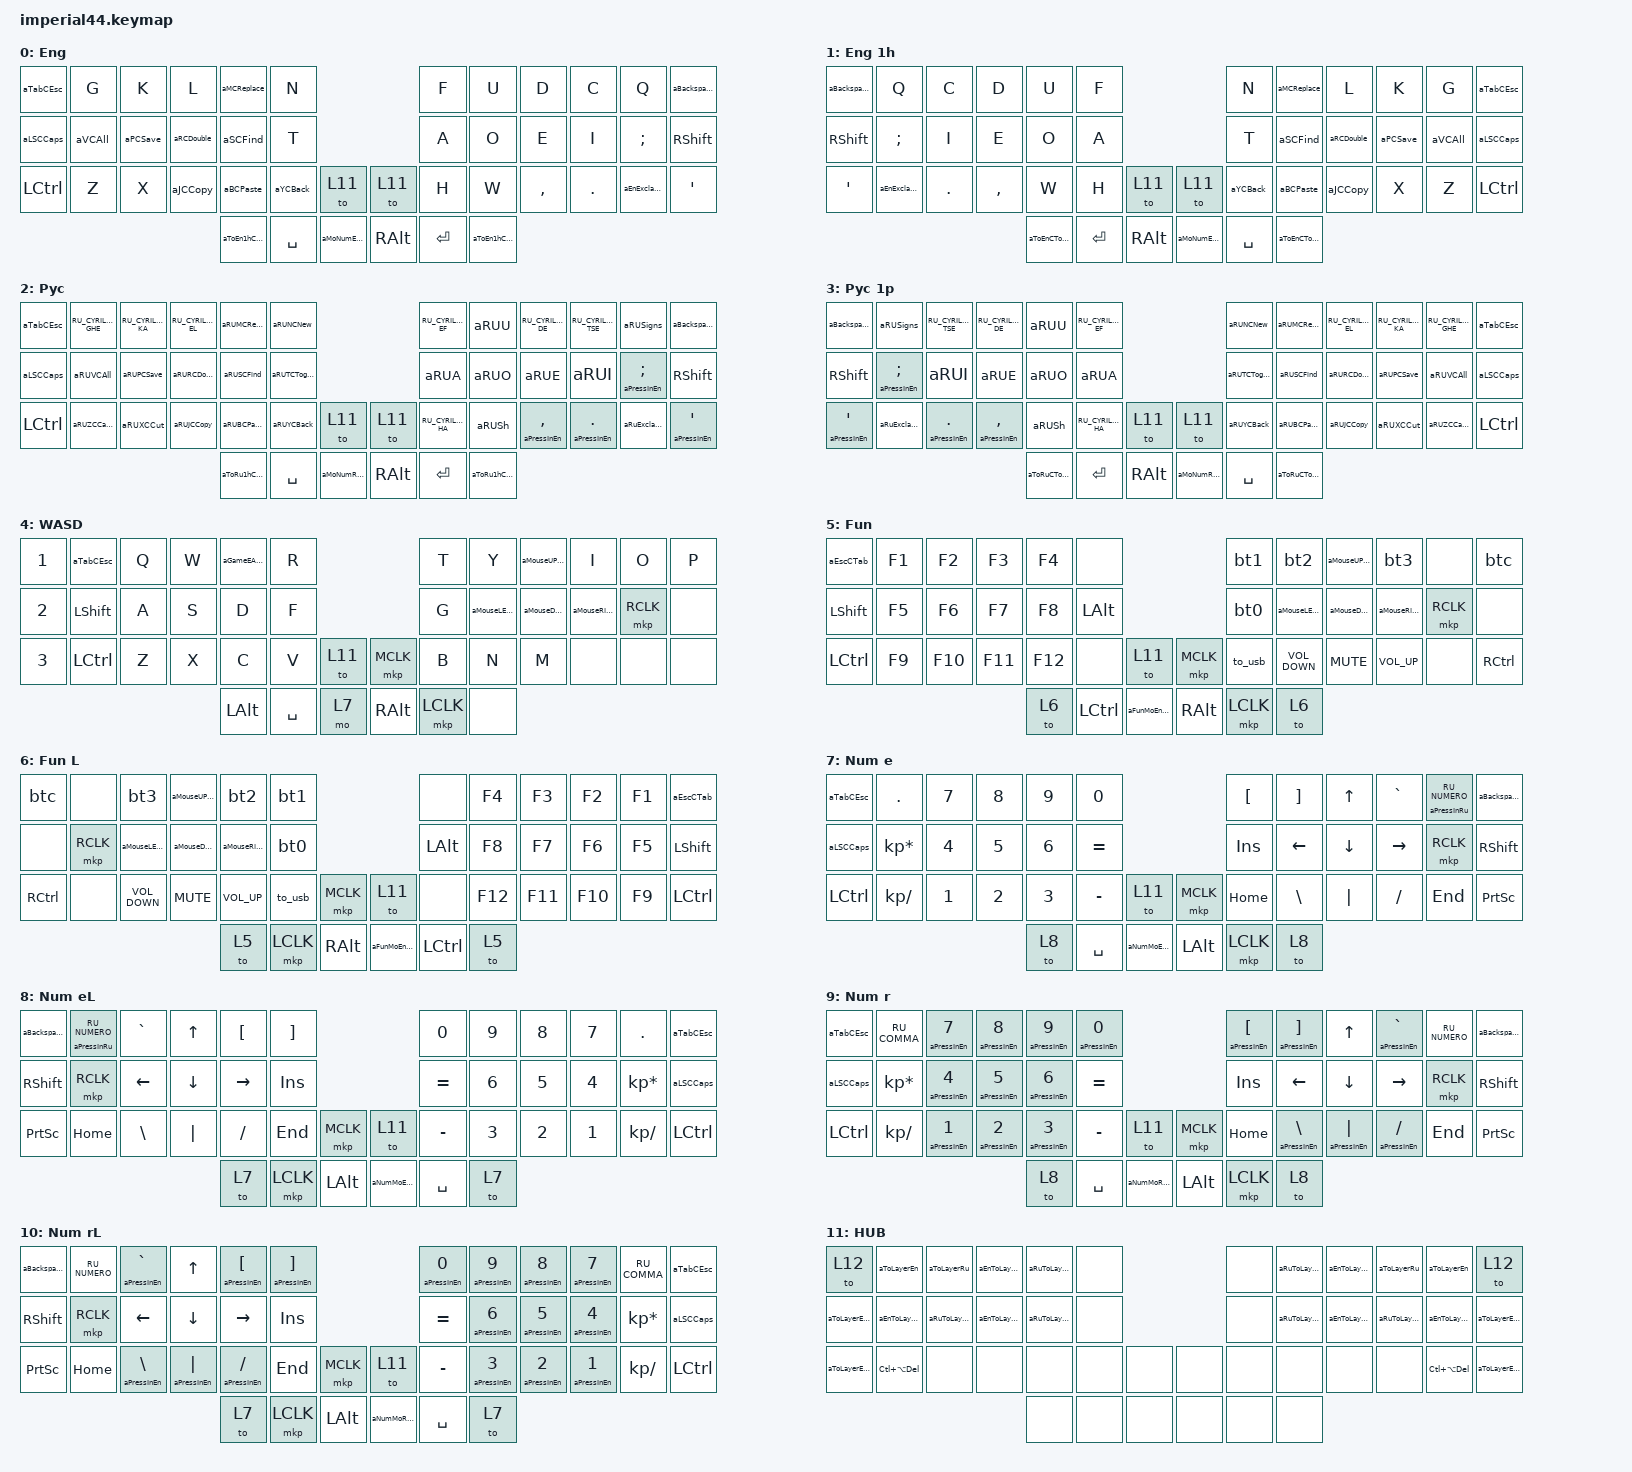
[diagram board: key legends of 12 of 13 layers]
#include "keys_ru.h"
#include <behaviors.dtsi>
#include <dt-bindings/zmk/bt.h>
#include <dt-bindings/zmk/keys.h>
#include <dt-bindings/zmk/outputs.h>
#include <dt-bindings/zmk/pointing.h>

/ {
    macros {
        aToLayerEn: toen {
            compatible = "zmk,behavior-macro";
            #binding-cells = <0>;
            bindings = <&aSwitchLangToEn &to 0>;
            label = "TOEN";
        };

        aToLayerRu: toru {
            compatible = "zmk,behavior-macro";
            #binding-cells = <0>;
            bindings = <&aSwitchLangToRu &to 2>;
            label = "TORU";
        };

        aSwitchLangToEn: aSwitchLangToEn {
            compatible = "zmk,behavior-macro";
            #binding-cells = <0>;
            bindings = <&kp LC(LS(NUMBER_1))>;
            label = "ASWITCHLANGTOEN";
        };

        aSwitchLangToRu: lang_ru {
            compatible = "zmk,behavior-macro";
            #binding-cells = <0>;
            bindings = <&kp LS(LC(NUMBER_2))>;
            label = "LANG_RU";
        };

        aPressInEn: en {
            compatible = "zmk,behavior-macro-one-param";
            #binding-cells = <1>;
            bindings =
                <&aSwitchLangToEn>,
                <&macro_press>,
                <&macro_param_1to1 &kp MACRO_PLACEHOLDER>,
                <&macro_pause_for_release>,
                <&macro_release>,
                <&macro_param_1to1 &kp MACRO_PLACEHOLDER>,
                <&macro_tap>,
                <&aSwitchLangToRu>;

            label = "EN";
        };

        to_bt0: to_bt0 {
            compatible = "zmk,behavior-macro";
            #binding-cells = <0>;
            bindings = <&out OUT_USB &bt BT_SEL 0 &out OUT_BLE &aToLayerEn>;
            label = "TO_BT0";
        };

        to_us: to_us {
            compatible = "zmk,behavior-macro";
            #binding-cells = <0>;
            bindings = <&out OUT_USB &aToLayerEn>;
            label = "TO_US";
        };

        to_bt1: to_bt1 {
            compatible = "zmk,behavior-macro";
            #binding-cells = <0>;
            bindings = <&out OUT_USB &bt BT_SEL 1 &out OUT_BLE &aToLayerEn>;
            label = "TO_BT1";
        };

        to_bt2: to_bt2 {
            compatible = "zmk,behavior-macro";
            #binding-cells = <0>;
            bindings = <&out OUT_USB &bt BT_SEL 2 &out OUT_BLE &aToLayerEn>;
            label = "TO_BT2";
        };

        to_bt3: to_bt3 {
            compatible = "zmk,behavior-macro";
            #binding-cells = <0>;
            bindings = <&out OUT_USB &bt BT_SEL 3 &out OUT_BLE &aToLayerEn>;
            label = "TO_BT3";
        };

        aToLayerEnAndLock: aLockToLayerEn {
            compatible = "zmk,behavior-macro";
            #binding-cells = <0>;
            bindings = <&aToLayerEn &kp LG(L)>;
            label = "ALOCKTOLAYEREN";
        };

        aEnToLayerGame: aEnToLayerGame {
            compatible = "zmk,behavior-macro";
            #binding-cells = <0>;
            bindings = <&aSwitchLangToEn &to 4>;
            label = "AENTOLAYERGAME";
        };

        aRuToLayerGame: aRuToLayerGame {
            compatible = "zmk,behavior-macro";
            #binding-cells = <0>;
            bindings = <&aSwitchLangToRu &to 4>;
            label = "ARUTOLAYERGAME";
        };

        aEnToLayerFun: aEnToLayerFun {
            compatible = "zmk,behavior-macro";
            #binding-cells = <0>;
            bindings = <&aSwitchLangToEn &to 5>;
            label = "AENTOLAYERFUN";
        };

        aRuToLayerFun: aRuToLayerFun {
            compatible = "zmk,behavior-macro";
            #binding-cells = <0>;
            bindings = <&aSwitchLangToRu &to 5>;
            label = "ARUTOLAYERFUN";
        };

        aEnToLayerNum: aEnToLayerNum {
            compatible = "zmk,behavior-macro";
            #binding-cells = <0>;
            bindings = <&aSwitchLangToEn &to 7>;
            label = "AENTOLAYERNUM";
        };

        aRuToLayerNum: aRuToLayerNum {
            compatible = "zmk,behavior-macro";
            #binding-cells = <0>;
            bindings = <&aSwitchLangToRu &to 9>;
            label = "ARUTOLAYERNUM";
        };

        aFunMoLayerEn: aFunMoLayerEn {
            compatible = "zmk,behavior-macro";
            #binding-cells = <0>;
            bindings =
                <&aSwitchLangToEn>,
                <&macro_tap>,
                <&to 0>,
                <&macro_pause_for_release>,
                <&macro_tap>,
                <&to 5>;

            label = "AFUNMOLAYEREN";
        };

        aFunMoLayerRu: aFunMoLayerRu {
            compatible = "zmk,behavior-macro";
            #binding-cells = <0>;
            bindings =
                <&aSwitchLangToRu>,
                <&macro_tap>,
                <&to 2>,
                <&macro_pause_for_release>,
                <&macro_tap>,
                <&to 5>;

            label = "AFUNMOLAYERRU";
        };

        aToLayerEnAndExec: aToLayerEnAndExec {
            compatible = "zmk,behavior-macro";
            #binding-cells = <0>;
            bindings = <&aToLayerEn &kp LG(R)>;
            label = "ATOLAYERENANDEXEC";
        };

        aPressInRu: aPressInRu {
            compatible = "zmk,behavior-macro-one-param";
            #binding-cells = <1>;
            bindings =
                <&aSwitchLangToRu>,
                <&macro_press>,
                <&macro_param_1to1 &kp MACRO_PLACEHOLDER>,
                <&macro_pause_for_release>,
                <&macro_release>,
                <&macro_param_1to1 &kp MACRO_PLACEHOLDER>,
                <&macro_tap>,
                <&aSwitchLangToEn>;

            label = "APRESSINRU";
        };

        aToRu1h: aToRu1h {
            compatible = "zmk,behavior-macro";
            #binding-cells = <0>;
            bindings = <&aSwitchLangToRu &to 3>;
            label = "ATORU1H";
        };

        aToEn1h: aToEn1h {
            compatible = "zmk,behavior-macro";
            #binding-cells = <0>;
            bindings = <&aSwitchLangToEn &to 1>;
            label = "ATOEN1H";
        };

        aNumMoLayerEn: aNumMoLayerEn {
            compatible = "zmk,behavior-macro";
            #binding-cells = <0>;
            bindings =
                <&aSwitchLangToEn>,
                <&macro_tap>,
                <&to 0>,
                <&macro_pause_for_release>,
                <&macro_tap>,
                <&to 7>;

            label = "ANUMMOLAYEREN";
        };

        aNumMoLayerRu: aNumMoLayerRu {
            compatible = "zmk,behavior-macro";
            #binding-cells = <0>;
            bindings =
                <&aSwitchLangToRu>,
                <&macro_tap>,
                <&to 2>,
                <&macro_pause_for_release>,
                <&macro_tap>,
                <&to 9>;

            label = "ANUMMOLAYERRU";
        };
    };

    behaviors {
        aEnExclamationSQuest: aEnExclamationSQuest {
            compatible = "zmk,behavior-mod-morph";
            label = "AENEXCLAMATIONSQUEST";
            bindings = <&kp EXCL>, <&kp QUESTION>;

            #binding-cells = <0>;
            mods = <(MOD_LSFT|MOD_RSFT)>;
        };

        aRUJCCopy: aRUJCCopy {
            compatible = "zmk,behavior-mod-morph";
            label = "ARUJCCOPY";
            bindings = <&kp RU_CYRILLIC_ZHE>, <&kp LC(C)>;

            #binding-cells = <0>;
            mods = <(MOD_LCTL|MOD_RCTL)>;
        };

        aRUBCPaste: aRUBCPaste {
            compatible = "zmk,behavior-mod-morph";
            label = "ARUBCPASTE";
            bindings = <&kp RU_CYRILLIC_BE>, <&kp LC(V)>;

            #binding-cells = <0>;
            mods = <(MOD_LCTL|MOD_RCTL)>;
        };

        aRUZCCancel: aRUZCCancel {
            compatible = "zmk,behavior-mod-morph";
            label = "ARUZCCANCEL";
            bindings = <&kp RU_CYRILLIC_ZE>, <&kp LC(Z)>;

            #binding-cells = <0>;
            mods = <(MOD_LCTL|MOD_RCTL)>;
        };

        aRUXCCut: aRUXCCut {
            compatible = "zmk,behavior-mod-morph";
            label = "ARUXCCUT";
            bindings = <&kp RU_CYRILLIC_CHE>, <&kp LC(X)>;

            #binding-cells = <0>;
            mods = <(MOD_LCTL|MOD_RCTL)>;
        };

        aRUVCAll: aRUVCAll {
            compatible = "zmk,behavior-mod-morph";
            label = "ARUVCALL";
            bindings = <&kp RU_CYRILLIC_VE>, <&kp LC(A)>;

            #binding-cells = <0>;
            mods = <(MOD_LCTL|MOD_RCTL)>;
        };

        aRUPCSave: aRUPCSave {
            compatible = "zmk,behavior-mod-morph";
            label = "ARUPCSAVE";
            bindings = <&kp RU_CYRILLIC_PE>, <&kp LC(S)>;

            #binding-cells = <0>;
            mods = <(MOD_LCTL|MOD_RCTL)>;
        };

        aRUMCReplace: aRUMCReplace {
            compatible = "zmk,behavior-mod-morph";
            label = "ARUMCREPLACE";
            bindings = <&kp RU_CYRILLIC_EM>, <&kp LC(R)>;

            #binding-cells = <0>;
            mods = <(MOD_LCTL|MOD_RCTL)>;
        };

        aRUTCToggle: aRUTCToggle {
            compatible = "zmk,behavior-mod-morph";
            label = "ARUTCTOGGLE";
            bindings = <&kp RU_CYRILLIC_TE>, <&kp LC(T)>;

            #binding-cells = <0>;
            mods = <(MOD_LCTL|MOD_RCTL)>;
        };

        aRUSCFind: aRUSCFind {
            compatible = "zmk,behavior-mod-morph";
            label = "ARUSCFIND";
            bindings = <&kp RU_CYRILLIC_ES>, <&kp LC(F)>;

            #binding-cells = <0>;
            mods = <(MOD_LCTL|MOD_RCTL)>;
        };

        aRUOCOpen: aRUOCOpen {
            compatible = "zmk,behavior-mod-morph";
            label = "ARUOCOPEN";
            bindings = <&kp RU_CYRILLIC_O>, <&kp LC(O)>;

            #binding-cells = <0>;
            mods = <(MOD_LCTL|MOD_RCTL)>;
        };

        aRUNCNew: aRUNCNew {
            compatible = "zmk,behavior-mod-morph";
            label = "ARUNCNEW";
            bindings = <&kp RU_CYRILLIC_EN>, <&kp LC(N)>;

            #binding-cells = <0>;
            mods = <(MOD_LCTL|MOD_RCTL)>;
        };

        aRUA: aRUA {
            compatible = "zmk,behavior-mod-morph";
            label = "ARUA";
            bindings = <&kp RU_CYRILLIC_A>, <&kp RU_CYRILLIC_YA>;

            #binding-cells = <0>;
            mods = <(MOD_LALT|MOD_RALT)>;
        };

        aRUO: aRUO {
            compatible = "zmk,behavior-mod-morph";
            label = "ARUO";
            bindings = <&aRUOCOpen>, <&kp RU_CYRILLIC_IO>;

            #binding-cells = <0>;
            mods = <(MOD_LALT|MOD_RALT)>;
        };

        aRUU: aRUU {
            compatible = "zmk,behavior-mod-morph";
            label = "ARUU";
            bindings = <&kp RU_CYRILLIC_U>, <&kp RU_CYRILLIC_YU>;

            #binding-cells = <0>;
            mods = <(MOD_RALT|MOD_LALT)>;
        };

        aRUE: aRUE {
            compatible = "zmk,behavior-mod-morph";
            label = "ARUE";
            bindings = <&kp RU_CYRILLIC_IE>, <&kp RU_CYRILLIC_E>;

            #binding-cells = <0>;
            mods = <(MOD_LALT|MOD_RALT)>;
        };

        aRUSigns: aRUSigns {
            compatible = "zmk,behavior-mod-morph";
            label = "ARUSIGNS";
            bindings = <&kp RU_CYRILLIC_SOFT_SIGN>, <&kp RU_CYRILLIC_HARD_SIGN>;

            #binding-cells = <0>;
            mods = <(MOD_LALT|MOD_RALT)>;
        };

        aRUSh: aRUSh {
            compatible = "zmk,behavior-mod-morph";
            label = "ARUSH";
            bindings = <&kp RU_CYRILLIC_SHA>, <&kp RU_CYRILLIC_SHCHA>;

            #binding-cells = <0>;
            mods = <(MOD_LALT|MOD_RALT)>;
        };

        aRUI: aRUI {
            compatible = "zmk,behavior-mod-morph";
            label = "ARUI";
            bindings = <&kp RU_CYRILLIC_I>, <&kp RU_CYRILLIC_SHORT_I>;

            #binding-cells = <0>;
            mods = <(MOD_LALT|MOD_RALT)>;
        };

        aJCCopy: aJCCopy {
            compatible = "zmk,behavior-mod-morph";
            label = "AJCCOPY";
            bindings = <&kp J>, <&kp LC(C)>;

            #binding-cells = <0>;
            mods = <(MOD_LCTL|MOD_RCTL)>;
        };

        aBCPaste: aBCPaste {
            compatible = "zmk,behavior-mod-morph";
            label = "ABCPASTE";
            bindings = <&kp B>, <&kp LC(V)>;

            #binding-cells = <0>;
            mods = <(MOD_LCTL|MOD_RCTL)>;
        };

        aVCAll: aVCAll {
            compatible = "zmk,behavior-mod-morph";
            label = "AVCALL";
            bindings = <&kp V>, <&kp LC(A)>;

            #binding-cells = <0>;
            mods = <(MOD_LCTL|MOD_RCTL)>;
        };

        aPCSave: aPCSave {
            compatible = "zmk,behavior-mod-morph";
            label = "APCSAVE";
            bindings = <&kp P>, <&kp LC(S)>;

            #binding-cells = <0>;
            mods = <(MOD_LCTL|MOD_RCTL)>;
        };

        aSCFind: aSCFind {
            compatible = "zmk,behavior-mod-morph";
            label = "ASCFIND";
            bindings = <&kp S>, <&kp LC(F)>;

            #binding-cells = <0>;
            mods = <(MOD_LCTL|MOD_RCTL)>;
        };

        aRuExclamationSQuest: aRuExclamationSQuest {
            compatible = "zmk,behavior-mod-morph";
            label = "ARUEXCLAMATIONSQUEST";
            bindings = <&kp RU_EXCLAMATION>, <&kp RU_QUESTION>;

            #binding-cells = <0>;
            mods = <(MOD_LSFT|MOD_RSFT)>;
        };

        to_usb: to_usb {
            compatible = "zmk,behavior-mod-morph";
            label = "TO_USB";
            bindings = <&none>, <&to_us>;

            #binding-cells = <0>;
            mods = <(MOD_RCTL)>;
        };

        bt0: bt0 {
            compatible = "zmk,behavior-mod-morph";
            label = "BT0";
            bindings = <&none>, <&to_bt0>;

            #binding-cells = <0>;
            mods = <(MOD_RCTL)>;
        };

        bt1: bt1 {
            compatible = "zmk,behavior-mod-morph";
            label = "BT1";
            bindings = <&none>, <&to_bt1>;

            #binding-cells = <0>;
            mods = <(MOD_RCTL)>;
        };

        bt2: bt2 {
            compatible = "zmk,behavior-mod-morph";
            label = "BT2";
            bindings = <&none>, <&to_bt2>;

            #binding-cells = <0>;
            mods = <(MOD_RCTL)>;
        };

        bt3: bt3 {
            compatible = "zmk,behavior-mod-morph";
            label = "BT3";
            bindings = <&none>, <&to_bt3>;

            #binding-cells = <0>;
            mods = <(MOD_RCTL)>;
        };

        btc: btc {
            compatible = "zmk,behavior-mod-morph";
            label = "BTC";
            bindings = <&none>, <&bt BT_CLR>;

            #binding-cells = <0>;
            mods = <(MOD_RCTL)>;
        };

        aMouseDOWNADOWN: aMouseDOWNADOWN {
            compatible = "zmk,behavior-mod-morph";
            label = "AMOUSEDOWNADOWN";
            bindings = <&mmv MOVE_DOWN>, <&kp DOWN_ARROW>;

            #binding-cells = <0>;
            mods = <(MOD_LALT|MOD_RALT)>;
        };

        aMouseLEFTALEFT: aMouseLEFTALEFT {
            compatible = "zmk,behavior-mod-morph";
            label = "AMOUSELEFTALEFT";
            bindings = <&mmv MOVE_LEFT>, <&kp LEFT_ARROW>;

            #binding-cells = <0>;
            mods = <(MOD_LALT|MOD_RALT)>;
        };

        aMouseRIGHTARIGHT: aMouseRIGHTARIGHT {
            compatible = "zmk,behavior-mod-morph";
            label = "AMOUSERIGHTARIGHT";
            bindings = <&mmv MOVE_RIGHT>, <&kp RIGHT_ARROW>;

            #binding-cells = <0>;
            mods = <(MOD_LALT|MOD_RALT)>;
        };

        aMouseUPAUP: aMouseUPAUP {
            compatible = "zmk,behavior-mod-morph";
            label = "AMOUSEUPAUP";
            bindings = <&mmv MOVE_UP>, <&kp UP_ARROW>;

            #binding-cells = <0>;
            mods = <(MOD_LALT|MOD_RALT)>;
        };

        aToEn1hCToRu: aToEn1hCToRu {
            compatible = "zmk,behavior-mod-morph";
            label = "ATOEN1HCTORU";
            bindings = <&to 1>, <&aToLayerRu>;

            #binding-cells = <0>;
            mods = <(MOD_LCTL|MOD_RCTL)>;
        };

        aToEnCToRu1h: aToEnCToRu1h {
            compatible = "zmk,behavior-mod-morph";
            label = "ATOENCTORU1H";
            bindings = <&to 0>, <&aToRu1h>;

            #binding-cells = <0>;
            mods = <(MOD_LCTL|MOD_RCTL)>;
        };

        aToRu1hCToEn: aToRu1hCToEn {
            compatible = "zmk,behavior-mod-morph";
            label = "ATORU1HCTOEN";
            bindings = <&to 3>, <&aToLayerEn>;

            #binding-cells = <0>;
            mods = <(MOD_LCTL|MOD_RCTL)>;
        };

        aToRuCToEn1h: aToRuCToEn1h {
            compatible = "zmk,behavior-mod-morph";
            label = "ATORUCTOEN1H";
            bindings = <&to 2>, <&aToEn1h>;

            #binding-cells = <0>;
            mods = <(MOD_LCTL|MOD_RCTL)>;
        };

        aTapNoneHoldToLayer: aTapNoneHoldToLayer {
            compatible = "zmk,behavior-hold-tap";
            label = "ATAPNONEHOLDTOLAYER";
            bindings = <&to>, <&none>;

            #binding-cells = <2>;
            tapping-term-ms = <500>;
        };

        aMoNumECToFun: aMoNumECToFun {
            compatible = "zmk,behavior-mod-morph";
            label = "AMONUMECTOFUN";
            bindings = <&mo 7>, <&to 5>;

            #binding-cells = <0>;
            mods = <(MOD_LCTL|MOD_RCTL)>;
        };

        aMoNumRCToFun: aMoNumRCToFun {
            compatible = "zmk,behavior-mod-morph";
            label = "AMONUMRCTOFUN";
            bindings = <&mo 9>, <&to 5>;

            #binding-cells = <0>;
            mods = <(MOD_LCTL|MOD_RCTL)>;
        };

        aTabCEsc: aTabCEsc {
            compatible = "zmk,behavior-mod-morph";
            label = "ATABCESC";
            bindings = <&kp TAB>, <&kp ESC>;

            #binding-cells = <0>;
            mods = <(MOD_LCTL|MOD_RCTL)>;
        };

        aLSCCaps: aLSCCaps {
            compatible = "zmk,behavior-mod-morph";
            label = "ALSCCAPS";
            bindings = <&kp LSHFT>, <&kp CAPS>;

            #binding-cells = <0>;
            mods = <(MOD_LCTL|MOD_RCTL)>;
        };

        aBackspaceSDelete: aBackspaceSDelete {
            compatible = "zmk,behavior-mod-morph";
            label = "ABACKSPACESDELETE";
            bindings = <&kp BACKSPACE>, <&kp DELETE>;

            #binding-cells = <0>;
            mods = <(MOD_LSFT|MOD_RSFT)>;
        };

        aRCDouble: aRCDouble {
            compatible = "zmk,behavior-mod-morph";
            label = "ARCDOUBLE";
            bindings = <&kp R>, <&kp LC(D)>;

            #binding-cells = <0>;
            mods = <(MOD_LCTL|MOD_RCTL)>;
        };

        aMCReplace: aMCReplace {
            compatible = "zmk,behavior-mod-morph";
            label = "AMCREPLACE";
            bindings = <&kp M>, <&kp LC(R)>;

            #binding-cells = <0>;
            mods = <(MOD_LCTL|MOD_RCTL)>;
        };

        aFunMoEnCToEn: aFunMoEnCToEn {
            compatible = "zmk,behavior-mod-morph";
            label = "AFUNMOENCTOEN";
            bindings = <&aFunMoLayerEn>, <&aToLayerEn>;

            #binding-cells = <0>;
            mods = <(MOD_LCTL|MOD_RCTL)>;
        };

        aYCBack: aYCBack {
            compatible = "zmk,behavior-mod-morph";
            label = "AYCBACK";
            bindings = <&kp Y>, <&kp LC(B)>;

            #binding-cells = <0>;
            mods = <(MOD_LCTL|MOD_RCTL)>;
        };

        aRUYCBack: aRUYCBack {
            compatible = "zmk,behavior-mod-morph";
            label = "ARUYCBACK";
            bindings = <&kp RU_CYRILLIC_YERU>, <&kp LC(B)>;

            #binding-cells = <0>;
            mods = <(MOD_LCTL|MOD_RCTL)>;
        };

        aRURCDouble: aRURCDouble {
            compatible = "zmk,behavior-mod-morph";
            label = "ARURCDOUBLE";
            bindings = <&kp RU_CYRILLIC_ER>, <&kp LC(D)>;

            #binding-cells = <0>;
            mods = <(MOD_LCTL|MOD_RCTL)>;
        };

        aMouseScroll: aMouseScroll {
            compatible = "zmk,behavior-sensor-rotate";
            label = "AMOUSESCROLL";
            #sensor-binding-cells = <0>;
            bindings = <&msc SCRL_UP>, <&msc SCRL_DOWN>;

            tap-ms = <200>;
        };

        aNumMoEnCToEn: aNumMoEnCToEn {
            compatible = "zmk,behavior-mod-morph";
            label = "ANUMMOENCTOEN";
            bindings = <&aNumMoLayerEn>, <&aToLayerEn>;

            #binding-cells = <0>;
            mods = <(MOD_LCTL|MOD_RCTL)>;
        };

        aNumMoRuCToRu: aNumMoRuCToRu {
            compatible = "zmk,behavior-mod-morph";
            label = "ANUMMORUCTORU";
            bindings = <&aNumMoLayerRu>, <&aToLayerRu>;

            #binding-cells = <0>;
            mods = <(MOD_LCTL|MOD_RCTL)>;
        };

        aGameEAEnter: aGameEAEnter {
            compatible = "zmk,behavior-mod-morph";
            label = "AGAMEEAENTER";
            bindings = <&kp E>, <&kp ENTER>;

            #binding-cells = <0>;
            mods = <(MOD_LALT|MOD_RALT)>;
        };

        aEscCTab: aEscCTab {
            compatible = "zmk,behavior-mod-morph";
            label = "AESCCTAB";
            bindings = <&kp ESC>, <&kp TAB>;

            #binding-cells = <0>;
            mods = <(MOD_LCTL|MOD_RCTL)>;
        };
    };

    combos { compatible = "zmk,combos"; };

    keymap {
        compatible = "zmk,keymap";

        wed {
            label = "Eng";
            bindings = <
&aTabCEsc  &kp G    &kp K     &kp L       &aMCReplace    &kp N                                  &kp F      &kp U          &kp D      &kp C    &kp Q                  &aBackspaceSDelete
&aLSCCaps  &aVCAll  &aPCSave  &aRCDouble  &aSCFind       &kp T                                  &kp A      &kp O          &kp E      &kp I    &kp SEMI               &kp RSHIFT
&kp LCTRL  &kp Z    &kp X     &aJCCopy    &aBCPaste      &aYCBack   &to 11            &to 11    &kp H      &kp W          &kp COMMA  &kp DOT  &aEnExclamationSQuest  &kp SINGLE_QUOTE
                                          &aToEn1hCToRu  &kp SPACE  &aMoNumECToFun    &kp RALT  &kp ENTER  &aToEn1hCToRu
            >;
        };

        wed1h {
            label = "Eng 1h";
            bindings = <
&aBackspaceSDelete  &kp Q                  &kp C    &kp D      &kp U          &kp F                                  &kp N      &aMCReplace    &kp L       &kp K     &kp G    &aTabCEsc
&kp RSHIFT          &kp SEMI               &kp I    &kp E      &kp O          &kp A                                  &kp T      &aSCFind       &aRCDouble  &aPCSave  &aVCAll  &aLSCCaps
&kp SINGLE_QUOTE    &aEnExclamationSQuest  &kp DOT  &kp COMMA  &kp W          &kp H      &to 11      &to 11          &aYCBack   &aBCPaste      &aJCCopy    &kp X     &kp Z    &kp LCTRL
                                                               &aToEnCToRu1h  &kp ENTER  &kp RALT    &aMoNumECToFun  &kp SPACE  &aToEnCToRu1h
            >;
        };

        wrd {
            bindings = <
&aTabCEsc  &kp RU_CYRILLIC_GHE  &kp RU_CYRILLIC_KA  &kp RU_CYRILLIC_EL  &aRUMCReplace  &aRUNCNew                                 &kp RU_CYRILLIC_EF  &aRUU          &kp RU_CYRILLIC_DE  &kp RU_CYRILLIC_TSE  &aRUSigns              &aBackspaceSDelete
&aLSCCaps  &aRUVCAll            &aRUPCSave          &aRURCDouble        &aRUSCFind     &aRUTCToggle                              &aRUA               &aRUO          &aRUE               &aRUI                &aPressInEn SEMICOLON  &kp RSHFT
&kp LCTRL  &aRUZCCancel         &aRUXCCut           &aRUJCCopy          &aRUBCPaste    &aRUYCBack    &to 11            &to 11    &kp RU_CYRILLIC_HA  &aRUSh         &aPressInEn COMMA   &aPressInEn DOT      &aRuExclamationSQuest  &aPressInEn SINGLE_QUOTE
                                                                        &aToRu1hCToEn  &kp SPACE     &aMoNumRCToFun    &kp RALT  &kp ENTER           &aToRu1hCToEn
            >;

            label = "Pyc";
        };

        wrd1h {
            bindings = <
&aBackspaceSDelete        &aRUSigns              &kp RU_CYRILLIC_TSE  &kp RU_CYRILLIC_DE  &aRUU          &kp RU_CYRILLIC_EF                              &aRUNCNew     &aRUMCReplace  &kp RU_CYRILLIC_EL  &kp RU_CYRILLIC_KA  &kp RU_CYRILLIC_GHE  &aTabCEsc
&kp RSHIFT                &aPressInEn SEMICOLON  &aRUI                &aRUE               &aRUO          &aRUA                                           &aRUTCToggle  &aRUSCFind     &aRURCDouble        &aRUPCSave          &aRUVCAll            &aLSCCaps
&aPressInEn SINGLE_QUOTE  &aRuExclamationSQuest  &aPressInEn DOT      &aPressInEn COMMA   &aRUSh         &kp RU_CYRILLIC_HA  &to 11      &to 11          &aRUYCBack    &aRUBCPaste    &aRUJCCopy          &aRUXCCut           &aRUZCCancel         &kp LCTRL
                                                                                          &aToRuCToEn1h  &kp ENTER           &kp RALT    &aMoNumRCToFun  &kp SPACE     &aToRuCToEn1h
            >;

            label = "Pyc 1p";
        };

        gm {
            bindings = <
&kp NUMBER_1  &aTabCEsc  &kp Q  &kp W  &aGameEAEnter  &kp R                           &kp T      &kp Y             &aMouseUPAUP      &kp I               &kp O      &kp P
&kp NUMBER_2  &kp LSHFT  &kp A  &kp S  &kp D          &kp F                           &kp G      &aMouseLEFTALEFT  &aMouseDOWNADOWN  &aMouseRIGHTARIGHT  &mkp RCLK  &none
&kp NUMBER_3  &kp LCTRL  &kp Z  &kp X  &kp C          &kp V      &to 11    &mkp MCLK  &kp B      &kp N             &kp M             &none               &none      &none
                                       &kp LALT       &kp SPACE  &mo 7     &kp RALT   &mkp LCLK  &none
            >;

            label = "WASD";
        };

        fune {
            bindings = <
&aEscCTab  &kp F1  &kp F2   &kp F3   &kp F4   &none                                   &bt1       &bt2               &aMouseUPAUP      &bt3                &none      &btc
&kp LSHFT  &kp F5  &kp F6   &kp F7   &kp F8   &kp LALT                                &bt0       &aMouseLEFTALEFT   &aMouseDOWNADOWN  &aMouseRIGHTARIGHT  &mkp RCLK  &none
&kp LCTRL  &kp F9  &kp F10  &kp F11  &kp F12  &none      &to 11            &mkp MCLK  &to_usb    &kp C_VOLUME_DOWN  &kp C_MUTE        &kp C_VOLUME_UP     &none      &kp RCTRL
                                     &to 6    &kp LCTRL  &aFunMoEnCToEn    &kp RALT   &mkp LCLK  &to 6
            >;

            display-name = "Fun";
        };

        fune1h {
            display-name = "Fun L";
            bindings = <
&btc       &none      &bt3               &aMouseUPAUP      &bt2                &bt1                                        &none      &kp F4   &kp F3   &kp F2   &kp F1  &aEscCTab
&none      &mkp RCLK  &aMouseLEFTALEFT   &aMouseDOWNADOWN  &aMouseRIGHTARIGHT  &bt0                                        &kp LALT   &kp F8   &kp F7   &kp F6   &kp F5  &kp LSHFT
&kp RCTRL  &none      &kp C_VOLUME_DOWN  &kp C_MUTE        &kp C_VOLUME_UP     &to_usb    &mkp MCLK        &to 11          &none      &kp F12  &kp F11  &kp F10  &kp F9  &kp LCTRL
                                                           &to 5               &mkp LCLK  &kp RIGHT_ALT    &aFunMoEnCToEn  &kp LCTRL  &to 5
            >;
        };

        nume {
            bindings = <
&aTabCEsc  &kp DOT          &kp NUMBER_7  &kp NUMBER_8  &kp NUMBER_9  &kp NUMBER_0                               &kp LBKT    &kp RBKT  &kp UP    &kp GRAVE  &aPressInRu RU_NUMERO  &aBackspaceSDelete
&aLSCCaps  &kp KP_MULTIPLY  &kp NUMBER_4  &kp NUMBER_5  &kp NUMBER_6  &kp EQUAL                                  &kp INSERT  &kp LEFT  &kp DOWN  &kp RIGHT  &mkp RCLK              &kp RSHIFT
&kp LCTRL  &kp KP_DIVIDE    &kp NUMBER_1  &kp NUMBER_2  &kp NUMBER_3  &kp MINUS     &to 11            &mkp MCLK  &kp HOME    &kp BSLH  &kp PIPE  &kp SLASH  &kp END                &kp PRINTSCREEN
                                                        &to 8         &kp SPACE     &aNumMoEnCToEn    &kp LALT   &mkp LCLK   &to 8
            >;

            display-name = "Num e";
            sensor-bindings =
                <&inc_dec_kp PAGE_UP PAGE_DOWN>,
                <&inc_dec_kp PAGE_UP PAGE_DOWN>;
        };

        nume1h {
            display-name = "Num eL";
            bindings = <
&aBackspaceSDelete  &aPressInRu RU_NUMERO  &kp GRAVE      &kp UP    &kp LBKT   &kp RIGHT_BRACKET                               &kp NUMBER_0  &kp NUMBER_9  &kp NUMBER_8  &kp NUMBER_7  &kp DOT          &aTabCEsc
&kp RSHIFT          &mkp RCLK              &kp LEFT       &kp DOWN  &kp RIGHT  &kp INSERT                                      &kp EQUAL     &kp NUMBER_6  &kp NUMBER_5  &kp NUMBER_4  &kp KP_MULTIPLY  &aLSCCaps
&kp PRINTSCREEN     &kp HOME               &kp BACKSLASH  &kp PIPE  &kp SLASH  &kp END            &mkp MCLK    &to 11          &kp MINUS     &kp NUMBER_3  &kp NUMBER_2  &kp NUMBER_1  &kp KP_DIVIDE    &kp LCTRL
                                                                    &to 7      &mkp LCLK          &kp LALT     &aNumMoEnCToEn  &kp SPACE     &to 7
            >;

            sensor-bindings =
                <&inc_dec_kp PAGE_UP PAGE_DOWN>,
                <&inc_dec_kp PAGE_UP PAGE_DOWN>;
        };

        numr {
            display-name = "Num r";
            bindings = <
&aTabCEsc  &kp RU_COMMA     &aPressInEn NUMBER_7  &aPressInEn NUMBER_8  &aPressInEn NUMBER_9  &aPressInEn NUMBER_0                               &aPressInEn LBKT  &aPressInEn RBKT  &kp UP            &aPressInEn GRAVE  &kp RU_NUMERO  &aBackspaceSDelete
&aLSCCaps  &kp KP_MULTIPLY  &aPressInEn NUMBER_4  &aPressInEn NUMBER_5  &aPressInEn NUMBER_6  &kp EQUAL                                          &kp INSERT        &kp LEFT          &kp DOWN          &kp RIGHT          &mkp RCLK      &kp RSHIFT
&kp LCTRL  &kp KP_DIVIDE    &aPressInEn NUMBER_1  &aPressInEn NUMBER_2  &aPressInEn NUMBER_3  &kp MINUS             &to 11            &mkp MCLK  &kp HOME          &aPressInEn BSLH  &aPressInEn PIPE  &aPressInEn SLASH  &kp END        &kp PRINTSCREEN
                                                                        &to 8                 &kp SPACE             &aNumMoRuCToRu    &kp LALT   &mkp LCLK         &to 8
            >;

            sensor-bindings =
                <&inc_dec_kp PAGE_UP PAGE_DOWN>,
                <&inc_dec_kp PAGE_UP PAGE_DOWN>;
        };

        numr1h {
            display-name = "Num rL";
            bindings = <
&aBackspaceSDelete  &kp RU_NUMERO  &aPressInEn GRAVE      &kp UP            &aPressInEn LEFT_BRACKET  &aPressInEn RIGHT_BRACKET                               &aPressInEn NUMBER_0  &aPressInEn NUMBER_9  &aPressInEn NUMBER_8  &aPressInEn NUMBER_7  &kp RU_COMMA     &aTabCEsc
&kp RSHIFT          &mkp RCLK      &kp LEFT               &kp DOWN          &kp RIGHT                 &kp INSERT                                              &kp EQUAL             &aPressInEn NUMBER_6  &aPressInEn NUMBER_5  &aPressInEn NUMBER_4  &kp KP_MULTIPLY  &aLSCCaps
&kp PRINTSCREEN     &kp HOME       &aPressInEn BACKSLASH  &aPressInEn PIPE  &aPressInEn SLASH         &kp END                    &mkp MCLK    &to 11          &kp MINUS             &aPressInEn NUMBER_3  &aPressInEn NUMBER_2  &aPressInEn NUMBER_1  &kp KP_DIVIDE    &kp LCTRL
                                                                            &to 7                     &mkp LCLK                  &kp LALT     &aNumMoRuCToRu  &kp SPACE             &to 7
            >;

            sensor-bindings =
                <&inc_dec_kp PAGE_UP PAGE_DOWN>,
                <&inc_dec_kp PAGE_UP PAGE_DOWN>;
        };

        hub {
            bindings = <
&to 12              &aToLayerEn         &aToLayerRu     &aEnToLayerGame  &aRuToLayerGame  &none                  &none  &aRuToLayerGame  &aEnToLayerGame  &aToLayerRu     &aToLayerEn         &to 12
&aToLayerEnAndExec  &aEnToLayerNum      &aRuToLayerNum  &aEnToLayerFun   &aRuToLayerFun   &none                  &none  &aRuToLayerFun   &aEnToLayerFun   &aRuToLayerNum  &aEnToLayerNum      &aToLayerEnAndExec
&aToLayerEnAndLock  &kp LC(LA(DELETE))  &none           &none            &none            &none  &none    &none  &none  &none            &none            &none           &kp LC(LA(DELETE))  &aToLayerEnAndLock
                                                                         &none            &none  &none    &none  &none  &none
            >;

            label = "HUB";
        };

        synth {
            bindings = <
&kp NUMBER_1  &kp Q  &kp W  &kp E  &kp R         &kp T                                                                 &kp Y         &kp U         &kp I      &kp O    &kp P     &kp EQUAL
&kp NUMBER_2  &kp A  &kp S  &kp D  &kp F         &kp G                                                                 &kp H         &kp J         &kp K      &kp L    &kp SEMI  &kp MINUS
&kp NUMBER_3  &kp Z  &kp X  &kp C  &kp V         &kp B         &aTapNoneHoldToLayer 11 0    &aTapNoneHoldToLayer 11 0  &kp N         &kp M         &kp COMMA  &kp DOT  &kp SQT   &kp NUMBER_0
                                   &kp NUMBER_4  &kp NUMBER_5  &kp NUMBER_6                 &kp NUMBER_7               &kp NUMBER_8  &kp NUMBER_9
            >;

            label = "SYNTH";
        };
    };
};
